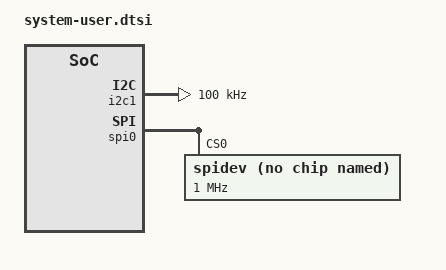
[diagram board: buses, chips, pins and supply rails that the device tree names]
/include/ "system-conf.dtsi"
/ {
};

/* Additional Changes for external interfaces */
&i2c1 {
    clock-frequency = <100000>;
};
/* SPI */
&spi0 {
      spidev@0x00 {
          compatible = "spidev";
	  spi-max-frequency = <1000000>;
	  reg = <0>;
	};
};
